# sysctl register map
Vendor: Texas Instruments
Peripheral module from a debugger description file (folder tm4e1111e6pdt).
Registers are 32-bit, read-write, no defined reset value unless marked. A register's access mark holds for its fields unless they carry their own. Offsets are as the file gives them; lines under a group give offsets from that group; [hi:lo] are bit positions; {n}, {i} and the like mark numbered series; 'fields as' and 'values as' point back to an identical list; <NAME> marks a mode.

## SYSCTL — System Control register addresses
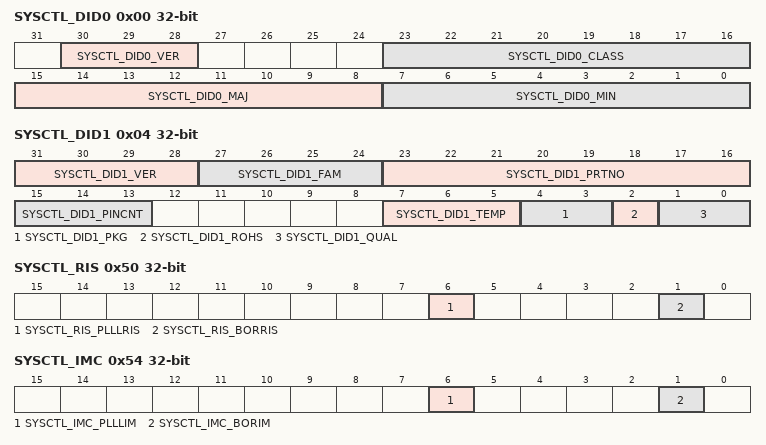
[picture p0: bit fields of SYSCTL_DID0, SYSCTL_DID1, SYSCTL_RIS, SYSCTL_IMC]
0x00 SYSCTL_DID0 ro — Device Identification 0
  [30:28] SYSCTL_DID0_VER — DID0 Version
    1=Second version of the DID0 register format
  [23:16] SYSCTL_DID0_CLASS — Device Class
    9=SYSCTL_DID0_CLASS_TM4E111 (Tiva(TM) TM4E111-class microcontrollers)
  [15:8] SYSCTL_DID0_MAJ — Major Revision
    0=SYSCTL_DID0_MAJ_REVA (Revision A (initial device)); 1=SYSCTL_DID0_MAJ_REVB (Revision B (first base layer revision)); 2=SYSCTL_DID0_MAJ_REVC (Revision C (second base layer revision))
  [7:0] SYSCTL_DID0_MIN — Minor Revision
    0=Initial device, or a major revision update; 1=First metal layer change; 2=Second metal layer change
0x04 SYSCTL_DID1 ro — Device Identification 1
  [31:28] SYSCTL_DID1_VER — DID1 Version
  [27:24] SYSCTL_DID1_FAM — Family
  [23:16] SYSCTL_DID1_PRTNO — Part Number
  [15:13] SYSCTL_DID1_PINCNT — Package Pin Count
    2=100-pin LQFP package; 3=64-pin LQFP package; 4=144-pin LQFP package; 5=157-pin BGA package; 6=128-pin TQFP package
  [7:5] SYSCTL_DID1_TEMP — Temperature Range
    0=SYSCTL_DID1_TEMP_C (Commercial temperature range); 1=SYSCTL_DID1_TEMP_I (Industrial temperature range); 2=SYSCTL_DID1_TEMP_E (Extended temperature range)
  [4:3] SYSCTL_DID1_PKG — Package Type
    1=SYSCTL_DID1_PKG_QFP (QFP package); 2=SYSCTL_DID1_PKG_BGA (BGA package)
  [2] SYSCTL_DID1_ROHS — RoHS-Compliance
  [1:0] SYSCTL_DID1_QUAL — Qualification Status
    0=SYSCTL_DID1_QUAL_ES (Engineering Sample (unqualified)); 1=SYSCTL_DID1_QUAL_PP (Pilot Production (unqualified)); 2=SYSCTL_DID1_QUAL_FQ (Fully Qualified)
0x30 SYSCTL_PBORCTL — Brown-Out Reset Control
  [1] SYSCTL_PBORCTL_BORIOR — BOR Interrupt or Reset
0x50 SYSCTL_RIS ro — Raw Interrupt Status
  [6] SYSCTL_RIS_PLLLRIS — PLL Lock Raw Interrupt Status
  [1] SYSCTL_RIS_BORRIS — Brown-Out Reset Raw Interrupt Status
0x54 SYSCTL_IMC — Interrupt Mask Control
  [6] SYSCTL_IMC_PLLLIM — PLL Lock Interrupt Mask
  [1] SYSCTL_IMC_BORIM — Brown-Out Reset Interrupt Mask
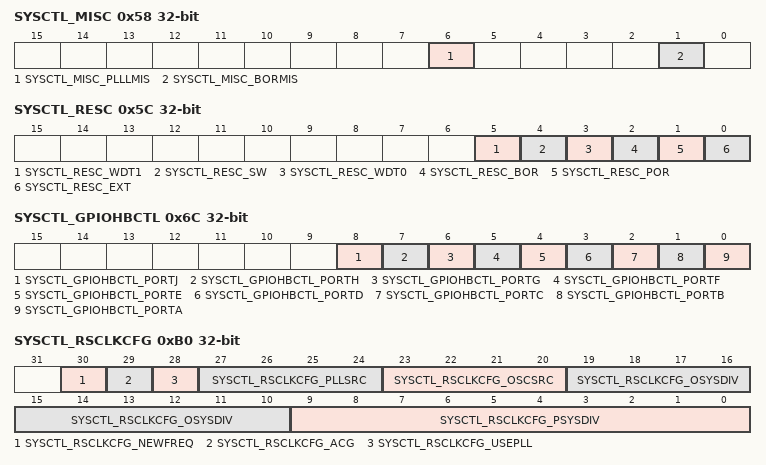
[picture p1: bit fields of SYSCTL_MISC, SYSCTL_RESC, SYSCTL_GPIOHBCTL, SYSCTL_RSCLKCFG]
0x58 SYSCTL_MISC — Masked Interrupt Status and Clear
  [6] SYSCTL_MISC_PLLLMIS — PLL Lock Masked Interrupt Status
  [1] SYSCTL_MISC_BORMIS — BOR Masked Interrupt Status
0x5C SYSCTL_RESC — Reset Cause
  [5] SYSCTL_RESC_WDT1 — Watchdog Timer 1 Reset
  [4] SYSCTL_RESC_SW — Software Reset
  [3] SYSCTL_RESC_WDT0 — Watchdog Timer 0 Reset
  [2] SYSCTL_RESC_BOR — Brown-Out Reset
  [1] SYSCTL_RESC_POR — Power-On Reset
  [0] SYSCTL_RESC_EXT — External Reset
0x6C SYSCTL_GPIOHBCTL — GPIO High-Performance Bus Control
  [8] SYSCTL_GPIOHBCTL_PORTJ — Port J Advanced High-Performance Bus
  [7] SYSCTL_GPIOHBCTL_PORTH — Port H Advanced High-Performance Bus
  [6] SYSCTL_GPIOHBCTL_PORTG — Port G Advanced High-Performance Bus
  [5] SYSCTL_GPIOHBCTL_PORTF — Port F Advanced High-Performance Bus
  [4] SYSCTL_GPIOHBCTL_PORTE — Port E Advanced High-Performance Bus
  [3] SYSCTL_GPIOHBCTL_PORTD — Port D Advanced High-Performance Bus
  [2] SYSCTL_GPIOHBCTL_PORTC — Port C Advanced High-Performance Bus
  [1] SYSCTL_GPIOHBCTL_PORTB — Port B Advanced High-Performance Bus
  [0] SYSCTL_GPIOHBCTL_PORTA — Port A Advanced High-Performance Bus
0xB0 SYSCTL_RSCLKCFG — Run and Sleep Mode Configuration Register
  [30] SYSCTL_RSCLKCFG_NEWFREQ — New PLLFREQ Accept
  [29] SYSCTL_RSCLKCFG_ACG — Auto Clock Gating
  [28] SYSCTL_RSCLKCFG_USEPLL — Use PLL
  [27:24] SYSCTL_RSCLKCFG_PLLSRC — PLL Source
    0=SYSCTL_RSCLKCFG_PLLSRC_PIOSC (PIOSC is PLL input clock source)
  [23:20] SYSCTL_RSCLKCFG_OSCSRC — Oscillator Source
    0=SYSCTL_RSCLKCFG_OSCSRC_PIOSC (PIOSC is oscillator source); 2=SYSCTL_RSCLKCFG_OSCSRC_LFIOSC (LFIOSC is oscillator source); 4=SYSCTL_RSCLKCFG_OSCSRC_RTC (Hibernation Module RTC Oscillator (RTCOSC))
  [19:10] SYSCTL_RSCLKCFG_OSYSDIV — Oscillator System Clock Divisor
  [9:0] SYSCTL_RSCLKCFG_PSYSDIV — PLL System Clock Divisor
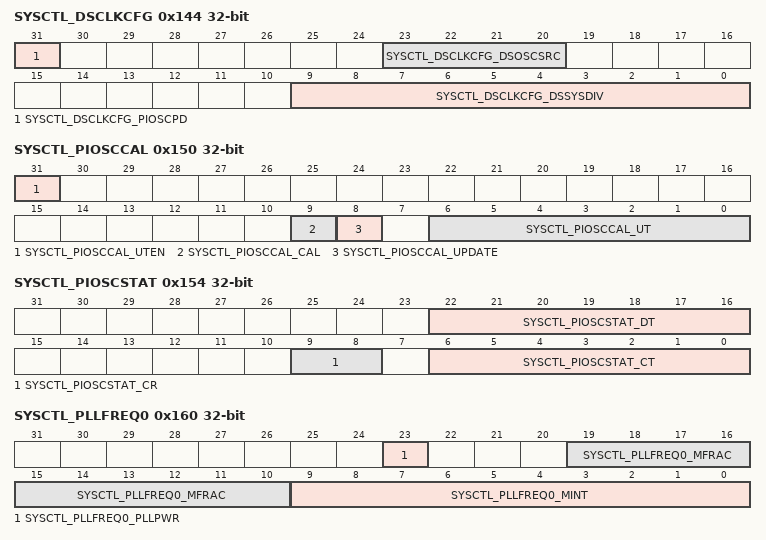
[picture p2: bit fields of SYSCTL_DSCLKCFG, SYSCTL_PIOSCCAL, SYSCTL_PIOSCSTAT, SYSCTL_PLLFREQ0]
0x144 SYSCTL_DSCLKCFG — Deep Sleep Clock Configuration Register
  [31] SYSCTL_DSCLKCFG_PIOSCPD — PIOSC Power Down
  [23:20] SYSCTL_DSCLKCFG_DSOSCSRC — Deep Sleep Oscillator Source
    0=SYSCTL_DSCLKCFG_DSOSCSRC_PIOSC (PIOSC); 2=SYSCTL_DSCLKCFG_DSOSCSRC_LFIOSC (LFIOSC); 4=SYSCTL_DSCLKCFG_DSOSCSRC_RTC (Hibernation Module RTCOSC)
  [9:0] SYSCTL_DSCLKCFG_DSSYSDIV — Deep Sleep Clock Divisor
0x14C SYSCTL_SYSPROP ro — System Properties
  [0] SYSCTL_SYSPROP_FPU — FPU Present
0x150 SYSCTL_PIOSCCAL — Precision Internal Oscillator Calibration
  [31] SYSCTL_PIOSCCAL_UTEN — Use User Trim Value
  [9] SYSCTL_PIOSCCAL_CAL — Start Calibration
  [8] SYSCTL_PIOSCCAL_UPDATE — Update Trim
  [6:0] SYSCTL_PIOSCCAL_UT — User Trim Value
0x154 SYSCTL_PIOSCSTAT ro — Precision Internal Oscillator Statistics
  [22:16] SYSCTL_PIOSCSTAT_DT — Default Trim Value
  [9:8] SYSCTL_PIOSCSTAT_CR — Calibration Result
    0=SYSCTL_PIOSCSTAT_CRNONE (Calibration has not been attempted); 1=SYSCTL_PIOSCSTAT_CRPASS (The last calibration operation completed to meet 1% accuracy); 2=SYSCTL_PIOSCSTAT_CRFAIL (The last calibration operation failed to meet 1% accuracy)
  [6:0] SYSCTL_PIOSCSTAT_CT — Calibration Trim Value
0x160 SYSCTL_PLLFREQ0 — PLL Frequency 0
  [23] SYSCTL_PLLFREQ0_PLLPWR — PLL Power
  [19:10] SYSCTL_PLLFREQ0_MFRAC — PLL M Fractional Value
  [9:0] SYSCTL_PLLFREQ0_MINT — PLL M Integer Value
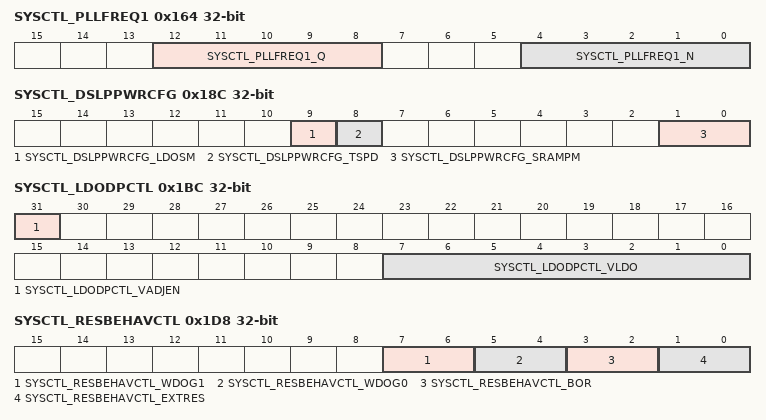
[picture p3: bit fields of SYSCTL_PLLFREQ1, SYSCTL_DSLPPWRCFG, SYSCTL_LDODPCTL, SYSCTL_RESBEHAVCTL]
0x164 SYSCTL_PLLFREQ1 — PLL Frequency 1
  [12:8] SYSCTL_PLLFREQ1_Q — PLL Q Value
  [4:0] SYSCTL_PLLFREQ1_N — PLL N Value
0x168 SYSCTL_PLLSTAT ro — PLL Status
  [0] SYSCTL_PLLSTAT_LOCK — PLL Lock
0x188 SYSCTL_SLPPWRCFG — Sleep Power Configuration
  [1:0] SYSCTL_SLPPWRCFG_SRAMPM — SRAM Power Modes
    0=SYSCTL_SLPPWRCFG_SRAMPM_NRM (Active Mode); 1=SYSCTL_SLPPWRCFG_SRAMPM_SBY (Standby Mode); 3=SYSCTL_SLPPWRCFG_SRAMPM_LP (Low Power Mode)
0x18C SYSCTL_DSLPPWRCFG — Deep-Sleep Power Configuration
  [9] SYSCTL_DSLPPWRCFG_LDOSM — LDO Sleep Mode
  [8] SYSCTL_DSLPPWRCFG_TSPD — Temperature Sense Power Down
  [1:0] SYSCTL_DSLPPWRCFG_SRAMPM — SRAM Power Modes
    0=SYSCTL_DSLPPWRCFG_SRAMPM_NRM (Active Mode); 1=SYSCTL_DSLPPWRCFG_SRAMPM_SBY (Standby Mode); 3=SYSCTL_DSLPPWRCFG_SRAMPM_LP (Low Power Mode)
0x1BC SYSCTL_LDODPCTL — LDO Deep-Sleep Power Control
  [31] SYSCTL_LDODPCTL_VADJEN — Voltage Adjust Enable
  [7:0] SYSCTL_LDODPCTL_VLDO — LDO Output Voltage
    18=SYSCTL_LDODPCTL_VLDO_0_90V (0.90 V); 19=SYSCTL_LDODPCTL_VLDO_0_95V (0.95 V); 20=SYSCTL_LDODPCTL_VLDO_1_00V (1.00 V); 21=SYSCTL_LDODPCTL_VLDO_1_05V (1.05 V); 22=SYSCTL_LDODPCTL_VLDO_1_10V (1.10 V); 23=SYSCTL_LDODPCTL_VLDO_1_15V (1.15 V); 24=SYSCTL_LDODPCTL_VLDO_1_20V (1.20 V); 25=SYSCTL_LDODPCTL_VLDO_1_25V (1.25 V); 26=SYSCTL_LDODPCTL_VLDO_1_30V (1.30 V); 27=SYSCTL_LDODPCTL_VLDO_1_35V (1.35 V)
0x1D8 SYSCTL_RESBEHAVCTL — Reset Behavior Control Register
  [7:6] SYSCTL_RESBEHAVCTL_WDOG1 — Watchdog 1 Reset Operation
    2=SYSCTL_RESBEHAVCTL_WDOG1_SYSRST (Watchdog 1 issues a system reset. The application starts within 10 us); 3=SYSCTL_RESBEHAVCTL_WDOG1_POR (Watchdog 1 issues a simulated POR sequence. Application starts less than 500 us after deassertion (Default))
  [5:4] SYSCTL_RESBEHAVCTL_WDOG0 — Watchdog 0 Reset Operation
    2=SYSCTL_RESBEHAVCTL_WDOG0_SYSRST (Watchdog 0 issues a system reset. The application starts within 10 us); 3=SYSCTL_RESBEHAVCTL_WDOG0_POR (Watchdog 0 issues a simulated POR sequence. Application starts less than 500 us after deassertion (Default))
  [3:2] SYSCTL_RESBEHAVCTL_BOR — BOR Reset operation
    2=SYSCTL_RESBEHAVCTL_BOR_SYSRST (Brown Out Reset issues system reset. The application starts within 10 us); 3=SYSCTL_RESBEHAVCTL_BOR_POR (Brown Out Reset issues a simulated POR sequence. The application starts less than 500 us after deassertion (Default))
  [1:0] SYSCTL_RESBEHAVCTL_EXTRES — External RST Pin Operation
    2=SYSCTL_RESBEHAVCTL_EXTRES_SYSRST (External RST assertion issues a system reset. The application starts within 10 us); 3=SYSCTL_RESBEHAVCTL_EXTRES_POR (External RST assertion issues a simulated POR sequence. Application starts less than 500 us after deassertion (Default))
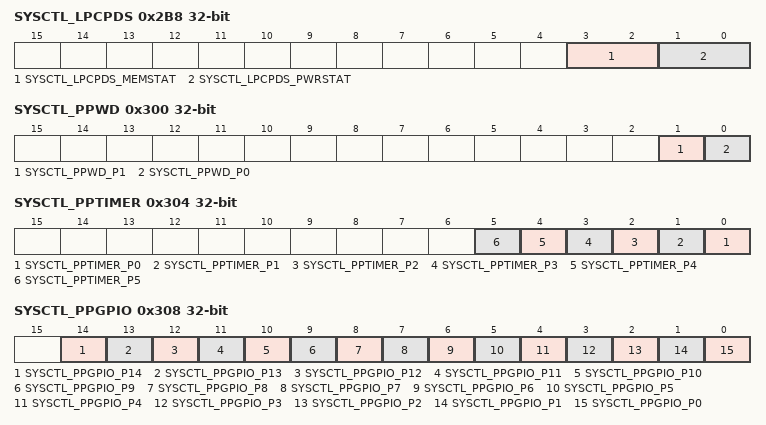
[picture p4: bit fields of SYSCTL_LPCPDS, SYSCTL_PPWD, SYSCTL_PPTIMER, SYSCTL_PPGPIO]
0x2B8 SYSCTL_LPCPDS ro — LPC Power Domain Status
  [3:2] SYSCTL_LPCPDS_MEMSTAT — Memory Array Power Status
    0=SYSCTL_LPCPDS_MEMSTAT_OFF (Array OFF); 3=SYSCTL_LPCPDS_MEMSTAT_ON (Array On)
  [1:0] SYSCTL_LPCPDS_PWRSTAT — Power Domain Status
    0=SYSCTL_LPCPDS_PWRSTAT_OFF (OFF); 3=SYSCTL_LPCPDS_PWRSTAT_ON (ON)
0x2BC SYSCTL_LPCMPC — LPC Memory Power Control
  [1:0] SYSCTL_LPCMPC_PWRCTL — Memory Array Power Control
    0=SYSCTL_LPCMPC_PWRCTL_OFF (Array OFF); 3=SYSCTL_LPCMPC_PWRCTL_ON (Array On)
0x300 SYSCTL_PPWD ro — Watchdog Timer Peripheral Present
  [1] SYSCTL_PPWD_P1 — Watchdog Timer 1 Present
  [0] SYSCTL_PPWD_P0 — Watchdog Timer 0 Present
0x304 SYSCTL_PPTIMER ro — 16/32-Bit General-Purpose Timer Peripheral Present
  [n] SYSCTL_PPTIMER_P{n} (n=0..5) — 16/32-Bit General-Purpose Timer {n} Present
0x308 SYSCTL_PPGPIO ro — General-Purpose Input/Output Peripheral Present
  [14] SYSCTL_PPGPIO_P14 — GPIO Port Q Present
  [13] SYSCTL_PPGPIO_P13 — GPIO Port P Present
  [12] SYSCTL_PPGPIO_P12 — GPIO Port N Present
  [11] SYSCTL_PPGPIO_P11 — GPIO Port M Present
  [10] SYSCTL_PPGPIO_P10 — GPIO Port L Present
  [9] SYSCTL_PPGPIO_P9 — GPIO Port K Present
  [8] SYSCTL_PPGPIO_P8 — GPIO Port J Present
  [7] SYSCTL_PPGPIO_P7 — GPIO Port H Present
  [6] SYSCTL_PPGPIO_P6 — GPIO Port G Present
  [5] SYSCTL_PPGPIO_P5 — GPIO Port F Present
  [4] SYSCTL_PPGPIO_P4 — GPIO Port E Present
  [3] SYSCTL_PPGPIO_P3 — GPIO Port D Present
  [2] SYSCTL_PPGPIO_P2 — GPIO Port C Present
  [1] SYSCTL_PPGPIO_P1 — GPIO Port B Present
  [0] SYSCTL_PPGPIO_P0 — GPIO Port A Present
0x30C SYSCTL_PPDMA ro — Micro Direct Memory Access Peripheral Present
  [0] SYSCTL_PPDMA_P0 — uDMA Module Present
0x310 SYSCTL_PPEPI ro — EPI Peripheral Present
  [0] SYSCTL_PPEPI_P0 — EPI Module Present
0x314 SYSCTL_PPHIB ro — Hibernation Peripheral Present
  [0] SYSCTL_PPHIB_P0 — Hibernation Module Present
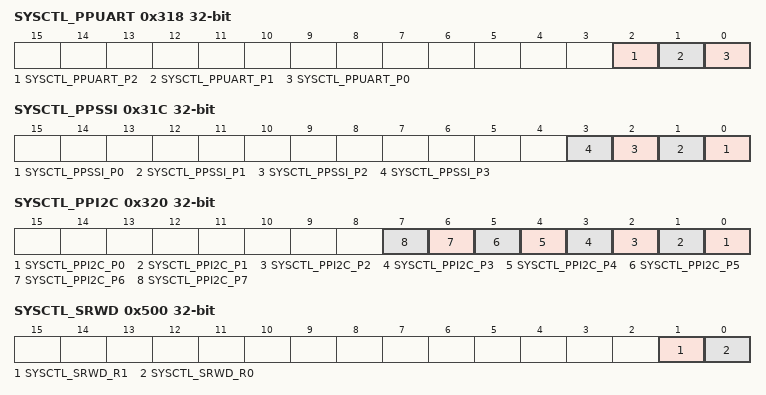
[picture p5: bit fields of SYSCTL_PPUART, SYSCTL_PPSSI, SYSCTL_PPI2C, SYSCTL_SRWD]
0x318 SYSCTL_PPUART ro — Universal Asynchronous Receiver/Transmitter Peripheral Present
  [2] SYSCTL_PPUART_P2 — UART Module 2 Present
  [1] SYSCTL_PPUART_P1 — UART Module 1 Present
  [0] SYSCTL_PPUART_P0 — UART Module 0 Present
0x31C SYSCTL_PPSSI ro — Synchronous Serial Interface Peripheral Present
  [n] SYSCTL_PPSSI_P{n} (n=0..3) — SSI Module {n} Present
0x320 SYSCTL_PPI2C ro — Inter-Integrated Circuit Peripheral Present
  [n] SYSCTL_PPI2C_P{n} (n=0..7) — I2C Module {n} Present
0x328 SYSCTL_PPUSB ro — Universal Serial Bus Peripheral Present
  [0] SYSCTL_PPUSB_P0 — USB Module Present
0x330 SYSCTL_PPEPHY ro — Ethernet PHY Peripheral Present
  [0] SYSCTL_PPEPHY_P0 — Ethernet PHY Module Present
0x334 SYSCTL_PPCAN ro — Controller Area Network Peripheral Present
  [0] SYSCTL_PPCAN_P0 — CAN Module 0 Present
0x338 SYSCTL_PPADC ro — Analog-to-Digital Converter Peripheral Present
  [0] SYSCTL_PPADC_P0 — ADC Module 0 Present
0x33C SYSCTL_PPACMP ro — Analog Comparator Peripheral Present
  [0] SYSCTL_PPACMP_P0 — Analog Comparator Module Present
0x340 SYSCTL_PPPWM ro — Pulse Width Modulator Peripheral Present
  [0] SYSCTL_PPPWM_P0 — PWM Module 0 Present
0x344 SYSCTL_PPQEI ro — Quadrature Encoder Interface Peripheral Present
  [0] SYSCTL_PPQEI_P0 — QEI Module 0 Present
0x348 SYSCTL_PPLPC ro — Low Pin Count Interface Peripheral Present
  [0] SYSCTL_PPLPC_P0 — LPC Module Present
0x350 SYSCTL_PPPECI ro — Platform Environment Control Interface Peripheral Present
  [0] SYSCTL_PPPECI_P0 — PECI Module Present
0x354 SYSCTL_PPFAN ro — Fan Control Peripheral Present
  [0] SYSCTL_PPFAN_P0 — FAN Module 0 Present
0x358 SYSCTL_PPEEPROM ro — EEPROM Peripheral Present
  [0] SYSCTL_PPEEPROM_P0 — EEPROM Module Present
0x35C SYSCTL_PPWTIMER ro — 32/64-Bit Wide General-Purpose Timer Peripheral Present
  [0] SYSCTL_PPWTIMER_P0 — 32/64-Bit Wide General-Purpose Timer 0 Present
0x398 SYSCTL_PPOWIRE ro — 1-Wire Peripheral Present
  [0] SYSCTL_PPOWIRE_P0 — 1-Wire Module Present
0x39C SYSCTL_PPEMAC ro — Ethernet MAC Peripheral Present
  [0] SYSCTL_PPEMAC_P0 — Ethernet Controller Module Present
0x3A4 SYSCTL_PPHIM ro — Human Interface Master Peripheral Present
  [0] SYSCTL_PPHIM_P0 — HIM Module Present
0x500 SYSCTL_SRWD — Watchdog Timer Software Reset
  [1] SYSCTL_SRWD_R1 — Watchdog Timer 1 Software Reset
  [0] SYSCTL_SRWD_R0 — Watchdog Timer 0 Software Reset
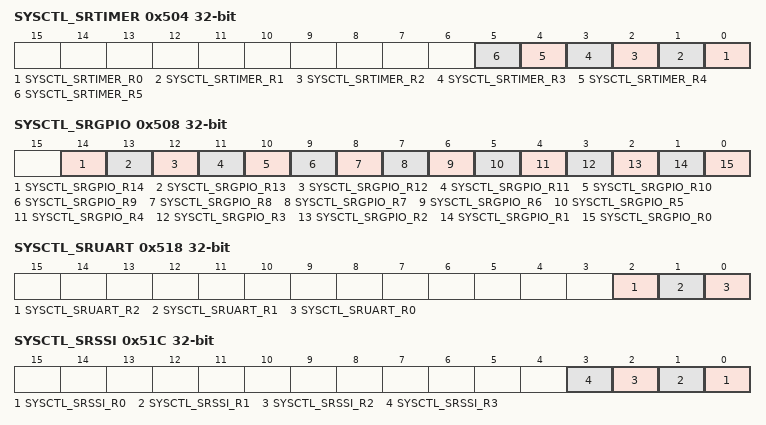
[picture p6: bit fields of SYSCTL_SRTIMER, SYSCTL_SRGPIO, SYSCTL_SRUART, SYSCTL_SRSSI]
0x504 SYSCTL_SRTIMER — 16/32-Bit General-Purpose Timer Software Reset
  [n] SYSCTL_SRTIMER_R{n} (n=0..5) — 16/32-Bit General-Purpose Timer {n} Software Reset
0x508 SYSCTL_SRGPIO — General-Purpose Input/Output Software Reset
  [14] SYSCTL_SRGPIO_R14 — GPIO Port Q Software Reset
  [13] SYSCTL_SRGPIO_R13 — GPIO Port P Software Reset
  [12] SYSCTL_SRGPIO_R12 — GPIO Port N Software Reset
  [11] SYSCTL_SRGPIO_R11 — GPIO Port M Software Reset
  [10] SYSCTL_SRGPIO_R10 — GPIO Port L Software Reset
  [9] SYSCTL_SRGPIO_R9 — GPIO Port K Software Reset
  [8] SYSCTL_SRGPIO_R8 — GPIO Port J Software Reset
  [7] SYSCTL_SRGPIO_R7 — GPIO Port H Software Reset
  [6] SYSCTL_SRGPIO_R6 — GPIO Port G Software Reset
  [5] SYSCTL_SRGPIO_R5 — GPIO Port F Software Reset
  [4] SYSCTL_SRGPIO_R4 — GPIO Port E Software Reset
  [3] SYSCTL_SRGPIO_R3 — GPIO Port D Software Reset
  [2] SYSCTL_SRGPIO_R2 — GPIO Port C Software Reset
  [1] SYSCTL_SRGPIO_R1 — GPIO Port B Software Reset
  [0] SYSCTL_SRGPIO_R0 — GPIO Port A Software Reset
0x50C SYSCTL_SRDMA — Micro Direct Memory Access Software Reset
  [0] SYSCTL_SRDMA_R0 — uDMA Module Software Reset
0x514 SYSCTL_SRHIB — Hibernation Software Reset
  [0] SYSCTL_SRHIB_R0 — Hibernation Module Software Reset
0x518 SYSCTL_SRUART — Universal Asynchronous Receiver/Transmitter Software Reset
  [2] SYSCTL_SRUART_R2 — UART Module 2 Software Reset
  [1] SYSCTL_SRUART_R1 — UART Module 1 Software Reset
  [0] SYSCTL_SRUART_R0 — UART Module 0 Software Reset
0x51C SYSCTL_SRSSI — Synchronous Serial Interface Software Reset
  [n] SYSCTL_SRSSI_R{n} (n=0..3) — SSI Module {n} Software Reset
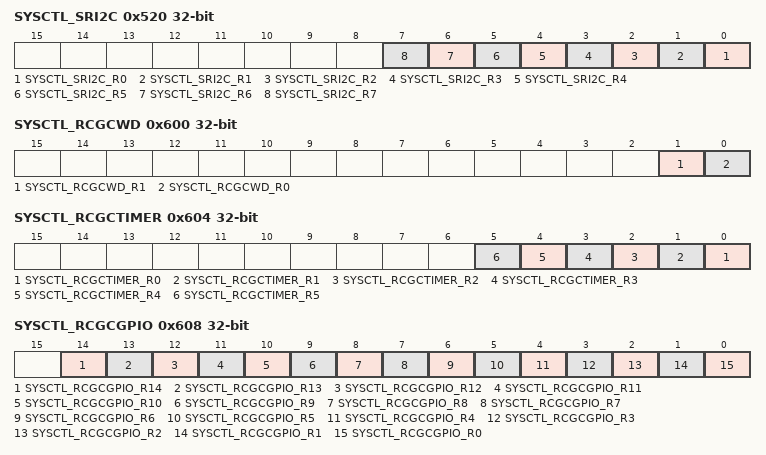
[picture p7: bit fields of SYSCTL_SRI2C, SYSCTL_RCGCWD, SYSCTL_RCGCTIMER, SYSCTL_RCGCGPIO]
0x520 SYSCTL_SRI2C — Inter-Integrated Circuit Software Reset
  [n] SYSCTL_SRI2C_R{n} (n=0..7) — I2C Module {n} Software Reset
0x538 SYSCTL_SRADC — Analog-to-Digital Converter Software Reset
  [0] SYSCTL_SRADC_R0 — ADC Module 0 Software Reset
0x53C SYSCTL_SRACMP — Analog Comparator Software Reset
  [0] SYSCTL_SRACMP_R0 — Analog Comparator Module 0 Software Reset
0x548 SYSCTL_SRLPC — Low Pin Count Interface Software Reset
  [0] SYSCTL_SRLPC_R0 — LPC Module Software Reset
0x550 SYSCTL_SRPECI — Platform Environment Control Interface Software Reset
  [0] SYSCTL_SRPECI_R0 — PECI Module Software Reset
0x554 SYSCTL_SRFAN — Fan Software Reset
  [0] SYSCTL_SRFAN_R0 — FAN 0 Module Software Reset
0x598 SYSCTL_SROWIRE — 1-Wire Software Reset
  [0] SYSCTL_SROWIRE_R0 — 1-Wire Module Software Reset
0x5A4 SYSCTL_SRHIM — Human Interface Master Software Reset
  [0] SYSCTL_SRHIM_R0 — HIM Module 0 Software Reset
0x600 SYSCTL_RCGCWD — Watchdog Timer Run Mode Clock Gating Control
  [1] SYSCTL_RCGCWD_R1 — Watchdog Timer 1 Run Mode Clock Gating Control
  [0] SYSCTL_RCGCWD_R0 — Watchdog Timer 0 Run Mode Clock Gating Control
0x604 SYSCTL_RCGCTIMER — 16/32-Bit General-Purpose Timer Run Mode Clock Gating Control
  [n] SYSCTL_RCGCTIMER_R{n} (n=0..5) — 16/32-Bit General-Purpose Timer {n} Run Mode Clock Gating Control
0x608 SYSCTL_RCGCGPIO — General-Purpose Input/Output Run Mode Clock Gating Control
  [14] SYSCTL_RCGCGPIO_R14 — GPIO Port Q Run Mode Clock Gating Control
  [13] SYSCTL_RCGCGPIO_R13 — GPIO Port P Run Mode Clock Gating Control
  [12] SYSCTL_RCGCGPIO_R12 — GPIO Port N Run Mode Clock Gating Control
  [11] SYSCTL_RCGCGPIO_R11 — GPIO Port M Run Mode Clock Gating Control
  [10] SYSCTL_RCGCGPIO_R10 — GPIO Port L Run Mode Clock Gating Control
  [9] SYSCTL_RCGCGPIO_R9 — GPIO Port K Run Mode Clock Gating Control
  [8] SYSCTL_RCGCGPIO_R8 — GPIO Port J Run Mode Clock Gating Control
  [7] SYSCTL_RCGCGPIO_R7 — GPIO Port H Run Mode Clock Gating Control
  [6] SYSCTL_RCGCGPIO_R6 — GPIO Port G Run Mode Clock Gating Control
  [5] SYSCTL_RCGCGPIO_R5 — GPIO Port F Run Mode Clock Gating Control
  [4] SYSCTL_RCGCGPIO_R4 — GPIO Port E Run Mode Clock Gating Control
  [3] SYSCTL_RCGCGPIO_R3 — GPIO Port D Run Mode Clock Gating Control
  [2] SYSCTL_RCGCGPIO_R2 — GPIO Port C Run Mode Clock Gating Control
  [1] SYSCTL_RCGCGPIO_R1 — GPIO Port B Run Mode Clock Gating Control
  [0] SYSCTL_RCGCGPIO_R0 — GPIO Port A Run Mode Clock Gating Control
0x60C SYSCTL_RCGCDMA — Micro Direct Memory Access Run Mode Clock Gating Control
  [0] SYSCTL_RCGCDMA_R0 — uDMA Module Run Mode Clock Gating Control
0x614 SYSCTL_RCGCHIB — Hibernation Run Mode Clock Gating Control
  [0] SYSCTL_RCGCHIB_R0 — Hibernation Module Run Mode Clock Gating Control
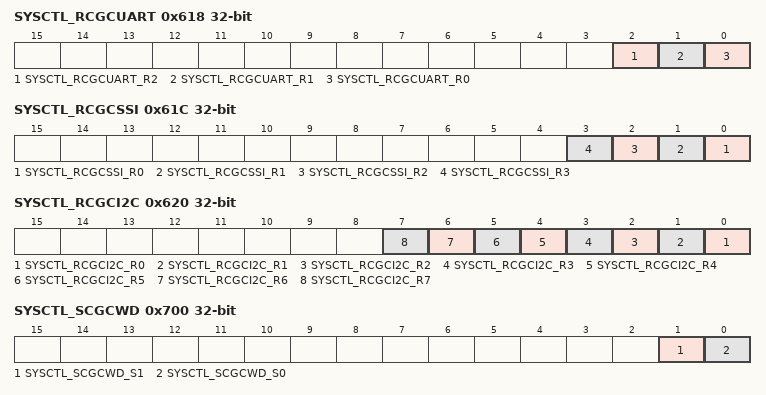
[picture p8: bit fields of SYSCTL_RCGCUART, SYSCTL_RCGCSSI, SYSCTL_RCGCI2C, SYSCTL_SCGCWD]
0x618 SYSCTL_RCGCUART — Universal Asynchronous Receiver/Transmitter Run Mode Clock Gating Control
  [2] SYSCTL_RCGCUART_R2 — UART Module 2 Run Mode Clock Gating Control
  [1] SYSCTL_RCGCUART_R1 — UART Module 1 Run Mode Clock Gating Control
  [0] SYSCTL_RCGCUART_R0 — UART Module 0 Run Mode Clock Gating Control
0x61C SYSCTL_RCGCSSI — Synchronous Serial Interface Run Mode Clock Gating Control
  [n] SYSCTL_RCGCSSI_R{n} (n=0..3) — SSI Module {n} Run Mode Clock Gating Control
0x620 SYSCTL_RCGCI2C — Inter-Integrated Circuit Run Mode Clock Gating Control
  [n] SYSCTL_RCGCI2C_R{n} (n=0..7) — I2C Module {n} Run Mode Clock Gating Control
0x638 SYSCTL_RCGCADC — Analog-to-Digital Converter Run Mode Clock Gating Control
  [0] SYSCTL_RCGCADC_R0 — ADC Module 0 Run Mode Clock Gating Control
0x63C SYSCTL_RCGCACMP — Analog Comparator Run Mode Clock Gating Control
  [0] SYSCTL_RCGCACMP_R0 — Analog Comparator Module 0 Run Mode Clock Gating Control
0x648 SYSCTL_RCGCLPC — Low Pin Count Interface Run Mode Clock Gating Control
  [0] SYSCTL_RCGCLPC_R0 — LPC Module Run Mode Clock Gating Control
0x650 SYSCTL_RCGCPECI — Platform Environment Control Interface Run Mode Clock Gating Control
  [0] SYSCTL_RCGCPECI_R0 — PECI Module Run Mode Clock Gating Control
0x654 SYSCTL_RCGCFAN — Fan Run Mode Clock Gating Control
  [0] SYSCTL_RCGCFAN_R0 — FAN Module 0 Run Mode Clock Gating Control
0x698 SYSCTL_RCGCOWIRE — 1-Wire Run Mode Clock Gating Control
  [0] SYSCTL_RCGCOWIRE_R0 — 1-Wire Module 0 Run Mode Clock Gating Control
0x6A4 SYSCTL_RCGCHIM — Human Interface Master Run Mode Clock Gating Control
  [0] SYSCTL_RCGCHIM_R0 — HIM Module 0 Run Mode Clock Gating Control
0x700 SYSCTL_SCGCWD — Watchdog Timer Sleep Mode Clock Gating Control
  [1] SYSCTL_SCGCWD_S1 — Watchdog Timer 1 Sleep Mode Clock Gating Control
  [0] SYSCTL_SCGCWD_S0 — Watchdog Timer 0 Sleep Mode Clock Gating Control
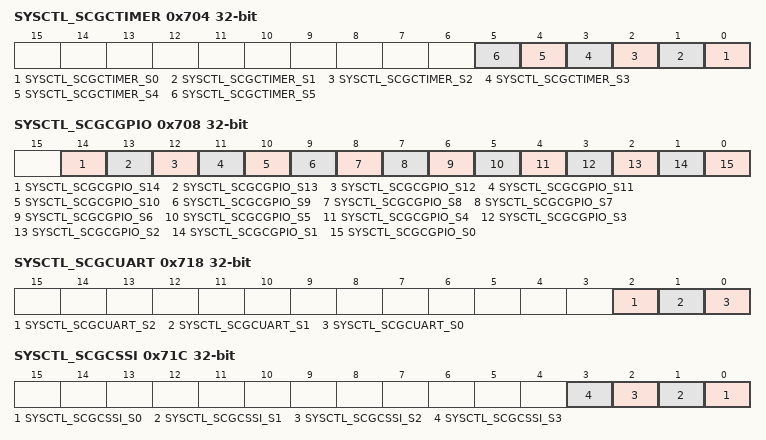
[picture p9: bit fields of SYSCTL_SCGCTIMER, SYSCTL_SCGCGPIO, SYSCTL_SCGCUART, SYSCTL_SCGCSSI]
0x704 SYSCTL_SCGCTIMER — 16/32-Bit General-Purpose Timer Sleep Mode Clock Gating Control
  [n] SYSCTL_SCGCTIMER_S{n} (n=0..5) — 16/32-Bit General-Purpose Timer {n} Sleep Mode Clock Gating Control
0x708 SYSCTL_SCGCGPIO — General-Purpose Input/Output Sleep Mode Clock Gating Control
  [14] SYSCTL_SCGCGPIO_S14 — GPIO Port Q Sleep Mode Clock Gating Control
  [13] SYSCTL_SCGCGPIO_S13 — GPIO Port P Sleep Mode Clock Gating Control
  [12] SYSCTL_SCGCGPIO_S12 — GPIO Port N Sleep Mode Clock Gating Control
  [11] SYSCTL_SCGCGPIO_S11 — GPIO Port M Sleep Mode Clock Gating Control
  [10] SYSCTL_SCGCGPIO_S10 — GPIO Port L Sleep Mode Clock Gating Control
  [9] SYSCTL_SCGCGPIO_S9 — GPIO Port K Sleep Mode Clock Gating Control
  [8] SYSCTL_SCGCGPIO_S8 — GPIO Port J Sleep Mode Clock Gating Control
  [7] SYSCTL_SCGCGPIO_S7 — GPIO Port H Sleep Mode Clock Gating Control
  [6] SYSCTL_SCGCGPIO_S6 — GPIO Port G Sleep Mode Clock Gating Control
  [5] SYSCTL_SCGCGPIO_S5 — GPIO Port F Sleep Mode Clock Gating Control
  [4] SYSCTL_SCGCGPIO_S4 — GPIO Port E Sleep Mode Clock Gating Control
  [3] SYSCTL_SCGCGPIO_S3 — GPIO Port D Sleep Mode Clock Gating Control
  [2] SYSCTL_SCGCGPIO_S2 — GPIO Port C Sleep Mode Clock Gating Control
  [1] SYSCTL_SCGCGPIO_S1 — GPIO Port B Sleep Mode Clock Gating Control
  [0] SYSCTL_SCGCGPIO_S0 — GPIO Port A Sleep Mode Clock Gating Control
0x714 SYSCTL_SCGCHIB — Hibernation Sleep Mode Clock Gating Control
  [0] SYSCTL_SCGCHIB_S0 — Hibernation Module Sleep Mode Clock Gating Control
0x718 SYSCTL_SCGCUART — Universal Asynchronous Receiver/Transmitter Sleep Mode Clock Gating Control
  [2] SYSCTL_SCGCUART_S2 — UART Module 2 Sleep Mode Clock Gating Control
  [1] SYSCTL_SCGCUART_S1 — UART Module 1 Sleep Mode Clock Gating Control
  [0] SYSCTL_SCGCUART_S0 — UART Module 0 Sleep Mode Clock Gating Control
0x71C SYSCTL_SCGCSSI — Synchronous Serial Interface Sleep Mode Clock Gating Control
  [n] SYSCTL_SCGCSSI_S{n} (n=0..3) — SSI Module {n} Sleep Mode Clock Gating Control
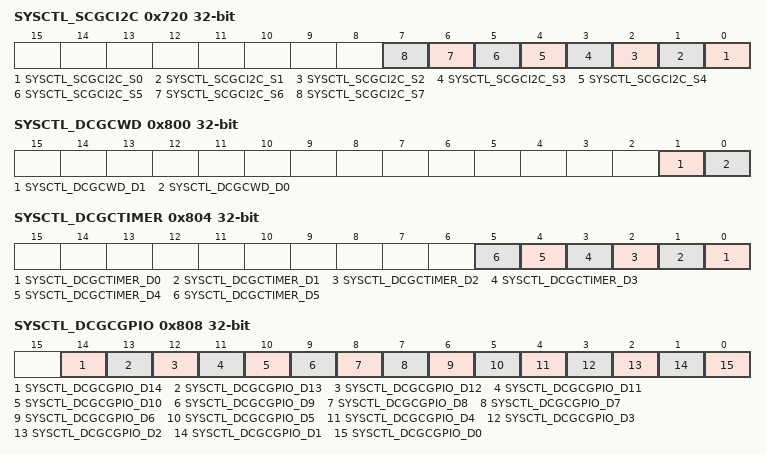
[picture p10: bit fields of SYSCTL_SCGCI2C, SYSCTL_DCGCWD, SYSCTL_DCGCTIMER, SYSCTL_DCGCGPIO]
0x720 SYSCTL_SCGCI2C — Inter-Integrated Circuit Sleep Mode Clock Gating Control
  [n] SYSCTL_SCGCI2C_S{n} (n=0..7) — I2C Module {n} Sleep Mode Clock Gating Control
0x738 SYSCTL_SCGCADC — Analog-to-Digital Converter Sleep Mode Clock Gating Control
  [0] SYSCTL_SCGCADC_S0 — ADC Module 0 Sleep Mode Clock Gating Control
0x73C SYSCTL_SCGCACMP — Analog Comparator Sleep Mode Clock Gating Control
  [0] SYSCTL_SCGCACMP_S0 — Analog Comparator Module 0 Sleep Mode Clock Gating Control
0x748 SYSCTL_SCGCLPC — Low Pin Count Interface Sleep Mode Clock Gating Control
  [0] SYSCTL_SCGCLPC_S0 — LPC Module Sleep Mode Clock Gating Control
0x750 SYSCTL_SCGCPECI — Platform Environment Control Interface Sleep Mode Clock Gating Control
  [0] SYSCTL_SCGCPECI_S0 — PECI Module Sleep Mode Clock Gating Control
0x754 SYSCTL_SCGCFAN — Fan Sleep Mode Clock Gating Control
  [0] SYSCTL_SCGCFAN_S0 — FAN Module Sleep Mode Clock Gating Control
0x798 SYSCTL_SCGCOWIRE — 1-Wire Sleep Mode Clock Gating Control
  [0] SYSCTL_SCGCOWIRE_S0 — 1-Wire Module 0 Sleep Mode Clock Gating Control
0x7A4 SYSCTL_SCGCHIM — Human Interface Master Sleep Mode Clock Gating Control
  [0] SYSCTL_SCGCHIM_S0 — HIM Module 0 Sleep Mode Clock Gating Control
0x800 SYSCTL_DCGCWD — Watchdog Timer Deep-Sleep Mode Clock Gating Control
  [1] SYSCTL_DCGCWD_D1 — Watchdog Timer 1 Deep-Sleep Mode Clock Gating Control
  [0] SYSCTL_DCGCWD_D0 — Watchdog Timer 0 Deep-Sleep Mode Clock Gating Control
0x804 SYSCTL_DCGCTIMER — 16/32-Bit General-Purpose Timer Deep-Sleep Mode Clock Gating Control
  [n] SYSCTL_DCGCTIMER_D{n} (n=0..5) — 16/32-Bit General-Purpose Timer {n} Deep-Sleep Mode Clock Gating Control
0x808 SYSCTL_DCGCGPIO — General-Purpose Input/Output Deep-Sleep Mode Clock Gating Control
  [14] SYSCTL_DCGCGPIO_D14 — GPIO Port Q Deep-Sleep Mode Clock Gating Control
  [13] SYSCTL_DCGCGPIO_D13 — GPIO Port P Deep-Sleep Mode Clock Gating Control
  [12] SYSCTL_DCGCGPIO_D12 — GPIO Port N Deep-Sleep Mode Clock Gating Control
  [11] SYSCTL_DCGCGPIO_D11 — GPIO Port M Deep-Sleep Mode Clock Gating Control
  [10] SYSCTL_DCGCGPIO_D10 — GPIO Port L Deep-Sleep Mode Clock Gating Control
  [9] SYSCTL_DCGCGPIO_D9 — GPIO Port K Deep-Sleep Mode Clock Gating Control
  [8] SYSCTL_DCGCGPIO_D8 — GPIO Port J Deep-Sleep Mode Clock Gating Control
  [7] SYSCTL_DCGCGPIO_D7 — GPIO Port H Deep-Sleep Mode Clock Gating Control
  [6] SYSCTL_DCGCGPIO_D6 — GPIO Port G Deep-Sleep Mode Clock Gating Control
  [5] SYSCTL_DCGCGPIO_D5 — GPIO Port F Deep-Sleep Mode Clock Gating Control
  [4] SYSCTL_DCGCGPIO_D4 — GPIO Port E Deep-Sleep Mode Clock Gating Control
  [3] SYSCTL_DCGCGPIO_D3 — GPIO Port D Deep-Sleep Mode Clock Gating Control
  [2] SYSCTL_DCGCGPIO_D2 — GPIO Port C Deep-Sleep Mode Clock Gating Control
  [1] SYSCTL_DCGCGPIO_D1 — GPIO Port B Deep-Sleep Mode Clock Gating Control
  [0] SYSCTL_DCGCGPIO_D0 — GPIO Port A Deep-Sleep Mode Clock Gating Control
0x814 SYSCTL_DCGCHIB — Hibernation Deep-Sleep Mode Clock Gating Control
  [0] SYSCTL_DCGCHIB_D0 — Hibernation Module Deep-Sleep Mode Clock Gating Control
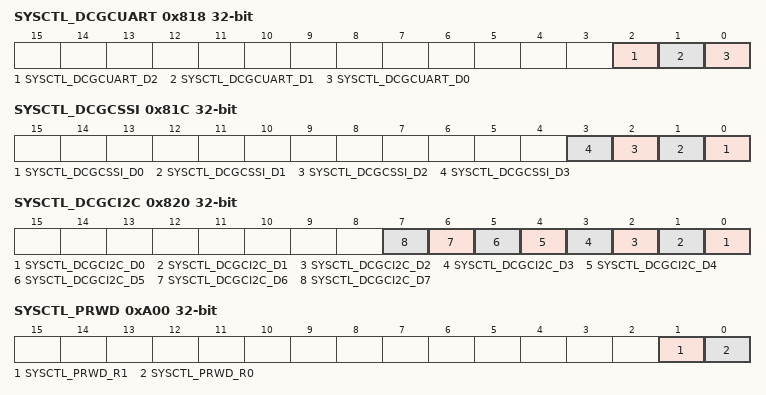
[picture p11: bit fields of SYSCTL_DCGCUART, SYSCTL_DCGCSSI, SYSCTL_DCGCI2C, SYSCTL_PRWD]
0x818 SYSCTL_DCGCUART — Universal Asynchronous Receiver/Transmitter Deep-Sleep Mode Clock Gating Control
  [2] SYSCTL_DCGCUART_D2 — UART Module 2 Deep-Sleep Mode Clock Gating Control
  [1] SYSCTL_DCGCUART_D1 — UART Module 1 Deep-Sleep Mode Clock Gating Control
  [0] SYSCTL_DCGCUART_D0 — UART Module 0 Deep-Sleep Mode Clock Gating Control
0x81C SYSCTL_DCGCSSI — Synchronous Serial Interface Deep-Sleep Mode Clock Gating Control
  [n] SYSCTL_DCGCSSI_D{n} (n=0..3) — SSI Module {n} Deep-Sleep Mode Clock Gating Control
0x820 SYSCTL_DCGCI2C — Inter-Integrated Circuit Deep-Sleep Mode Clock Gating Control
  [n] SYSCTL_DCGCI2C_D{n} (n=0..7) — I2C Module {n} Deep-Sleep Mode Clock Gating Control
0x838 SYSCTL_DCGCADC — Analog-to-Digital Converter Deep-Sleep Mode Clock Gating Control
  [0] SYSCTL_DCGCADC_D0 — ADC Module 0 Deep-Sleep Mode Clock Gating Control
0x83C SYSCTL_DCGCACMP — Analog Comparator Deep-Sleep Mode Clock Gating Control
  [0] SYSCTL_DCGCACMP_D0 — Analog Comparator Module 0 Deep-Sleep Mode Clock Gating Control
0x848 SYSCTL_DCGCLPC — Low Pin Count Interface Deep-Sleep Mode Clock Gating Control
  [0] SYSCTL_DCGCLPC_D0 — LPC Module Deep-Sleep Mode Clock Gating Control
0x850 SYSCTL_DCGCPECI — Platform Environment Control Interface Deep-Sleep Mode Clock Gating Control
  [0] SYSCTL_DCGCPECI_D0 — PECI Module Deep-Sleep Mode Clock Gating Control
0x854 SYSCTL_DCGCFAN — Fan Deep-Sleep Mode Clock Gating Control
  [0] SYSCTL_DCGCFAN_D0 — FAN Module 0 Deep-Sleep Mode Clock Gating Control
0x898 SYSCTL_DCGCOWIRE — 1-Wire Deep-Sleep Mode Clock Gating Control
  [0] SYSCTL_DCGCOWIRE_D0 — 1-Wire Module 0 Deep-Sleep Mode Clock Gating Control
0x8A4 SYSCTL_DCGCHIM — Human Interface Master Deep-Sleep Mode Clock Gating Control
  [0] SYSCTL_DCGCHIM_D0 — HIM Module 0 Deep-Sleep Mode Clock Gating Control
0xA00 SYSCTL_PRWD ro — Watchdog Timer Peripheral Ready
  [1] SYSCTL_PRWD_R1 — Watchdog Timer 1 Peripheral Ready
  [0] SYSCTL_PRWD_R0 — Watchdog Timer 0 Peripheral Ready
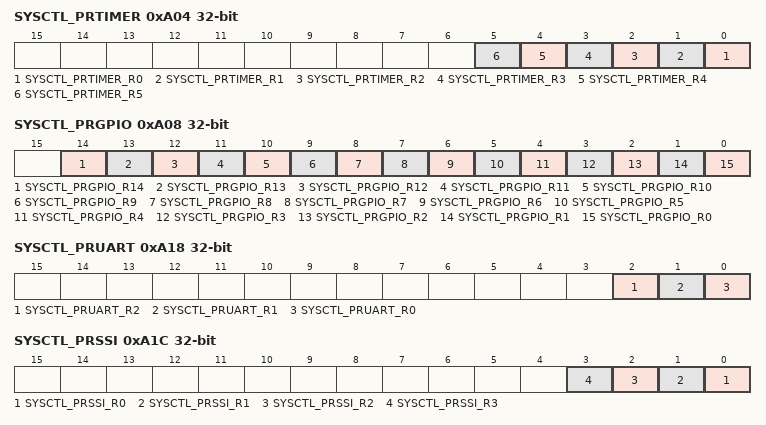
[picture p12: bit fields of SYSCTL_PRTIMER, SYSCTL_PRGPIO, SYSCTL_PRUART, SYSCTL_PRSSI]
0xA04 SYSCTL_PRTIMER ro — 16/32-Bit General-Purpose Timer Peripheral Ready
  [n] SYSCTL_PRTIMER_R{n} (n=0..5) — 16/32-Bit General-Purpose Timer {n} Peripheral Ready
0xA08 SYSCTL_PRGPIO ro — General-Purpose Input/Output Peripheral Ready
  [14] SYSCTL_PRGPIO_R14 — GPIO Port Q Peripheral Ready
  [13] SYSCTL_PRGPIO_R13 — GPIO Port P Peripheral Ready
  [12] SYSCTL_PRGPIO_R12 — GPIO Port N Peripheral Ready
  [11] SYSCTL_PRGPIO_R11 — GPIO Port M Peripheral Ready
  [10] SYSCTL_PRGPIO_R10 — GPIO Port L Peripheral Ready
  [9] SYSCTL_PRGPIO_R9 — GPIO Port K Peripheral Ready
  [8] SYSCTL_PRGPIO_R8 — GPIO Port J Peripheral Ready
  [7] SYSCTL_PRGPIO_R7 — GPIO Port H Peripheral Ready
  [6] SYSCTL_PRGPIO_R6 — GPIO Port G Peripheral Ready
  [5] SYSCTL_PRGPIO_R5 — GPIO Port F Peripheral Ready
  [4] SYSCTL_PRGPIO_R4 — GPIO Port E Peripheral Ready
  [3] SYSCTL_PRGPIO_R3 — GPIO Port D Peripheral Ready
  [2] SYSCTL_PRGPIO_R2 — GPIO Port C Peripheral Ready
  [1] SYSCTL_PRGPIO_R1 — GPIO Port B Peripheral Ready
  [0] SYSCTL_PRGPIO_R0 — GPIO Port A Peripheral Ready
0xA0C SYSCTL_PRDMA ro — Micro Direct Memory Access Peripheral Ready
  [0] SYSCTL_PRDMA_R0 — uDMA Module Peripheral Ready
0xA14 SYSCTL_PRHIB ro — Hibernation Peripheral Ready
  [0] SYSCTL_PRHIB_R0 — Hibernation Module Peripheral Ready
0xA18 SYSCTL_PRUART ro — Universal Asynchronous Receiver/Transmitter Peripheral Ready
  [2] SYSCTL_PRUART_R2 — UART Module 2 Peripheral Ready
  [1] SYSCTL_PRUART_R1 — UART Module 1 Peripheral Ready
  [0] SYSCTL_PRUART_R0 — UART Module 0 Peripheral Ready
0xA1C SYSCTL_PRSSI ro — Synchronous Serial Interface Peripheral Ready
  [n] SYSCTL_PRSSI_R{n} (n=0..3) — SSI Module {n} Peripheral Ready
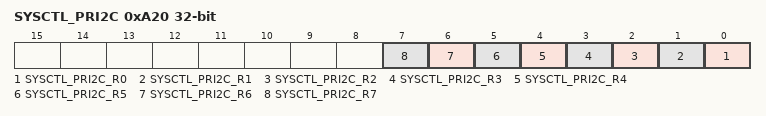
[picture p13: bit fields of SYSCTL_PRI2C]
0xA20 SYSCTL_PRI2C ro — Inter-Integrated Circuit Peripheral Ready
  [n] SYSCTL_PRI2C_R{n} (n=0..7) — I2C Module {n} Peripheral Ready
0xA38 SYSCTL_PRADC ro — Analog-to-Digital Converter Peripheral Ready
  [0] SYSCTL_PRADC_R0 — ADC Module 0 Peripheral Ready
0xA3C SYSCTL_PRACMP ro — Analog Comparator Peripheral Ready
  [0] SYSCTL_PRACMP_R0 — Analog Comparator Module 0 Peripheral Ready
0xA48 SYSCTL_PRLPC ro — Low Pin Count Interface Peripheral Ready
  [0] SYSCTL_PRLPC_R0 — LPC Module Peripheral Ready
0xA50 SYSCTL_PRPECI ro — Platform Environment Control Interface Peripheral Ready
  [0] SYSCTL_PRPECI_R0 — PECI Module Peripheral Ready
0xA54 SYSCTL_PRFAN ro — Fan Peripheral Ready
  [0] SYSCTL_PRFAN_R0 — FAN Module Peripheral Ready
0xA98 SYSCTL_PROWIRE ro — 1-Wire Peripheral Ready
  [0] SYSCTL_PROWIRE_R0 — 1-Wire Module 0 Peripheral Ready
0xAA4 SYSCTL_PRHIM ro — Human Interface Master Peripheral Ready
  [0] SYSCTL_PRHIM_R0 — HIM Module 0 Peripheral Ready
